# AT32F413 register map
Vendor: Keil; Series: AT32F413; File version: 1.0
CPU: CM4 r0p1, little endian, no MPU, FPU, 4 interrupt priority bits
Registers are 32-bit, read-write, reset 0x0 unless marked. A register's access mark holds for its fields unless they carry their own. Offsets are from the block's base; [hi:lo] are bit positions; {n}, {i} and the like mark numbered series; 'fields as' and 'values as' point back to an identical list.

## EXINT
Base 0x40010400
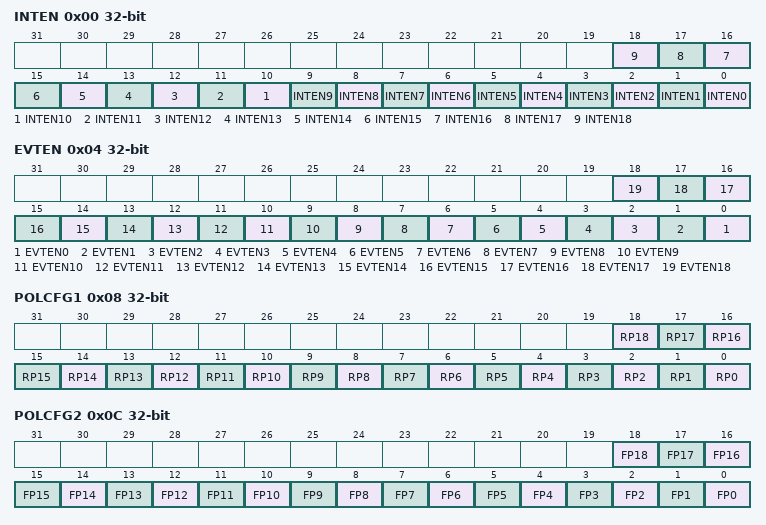
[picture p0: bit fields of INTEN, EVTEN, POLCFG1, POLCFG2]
0x00 INTEN — Interrupt enable register
  [n] INTEN{n} (n=0..18) — Interrupt enable or disable on line {n}
    on read: 0=Disabled (Interrupt request is disabled); 1=Enabled (Interrupt request is enabled) | on write: 0=Disable (Interrupt request disable); 1=Enable (Interrupt request enable)
0x04 EVTEN — Event enable register
  [n] EVTEN{n} (n=0..18) — Event enable or disable on line {n}
    on read: 0=Disabled (Event request is disabled); 1=Enabled (Event request is enabled) | on write: 0=Disable (Event request disable); 1=Enable (Event request enable)
0x08 POLCFG1 — Rising polarity configuration register
  [n] RP{n} (n=0..18) — Rising polarity configuration bit on line {n}
    on read: 0=Disabled (Rising trigger is disabled); 1=Enabled (Rising trigger is enabled) | on write: 0=Disable (Rising trigger disable); 1=Enable (Rising trigger enable)
0x0C POLCFG2 — Falling polarity configuration register
  [n] FP{n} (n=0..18) — Falling polarity configuration bit on line {n}
    on read: 0=Disabled (Falling polarity is disabled); 1=Enabled (Falling polarity is enabled) | on write: 0=Disable (Falling polarity disable); 1=Enable (Falling polarity enable)
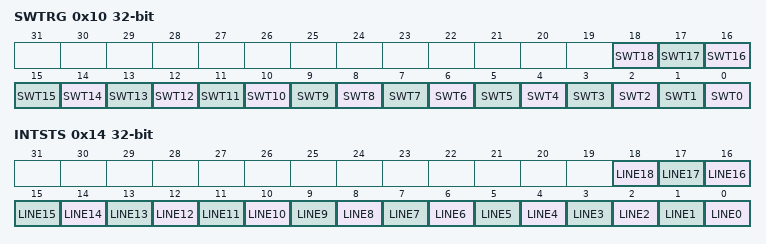
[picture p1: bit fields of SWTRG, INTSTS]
0x10 SWTRG — Software triggle register
  [n] SWT{n} (n=0..18) write-1-sets — Software trigger on line {n}
    on read: 0=NoTrigger (Default value); 1=Triggered (Software trigger generated) | on write: 1=Trigger (Generate trigger)
0x14 INTSTS — Interrupt status register
  [n] LINE{n} (n=0..18) write-1-clears — Line {n} status bit
    on read: 0=No interrupt occurred; 1=Interrupt occurred | on write: 1=Clear status flag

## RTC — Real time clock
Base 0x40002800
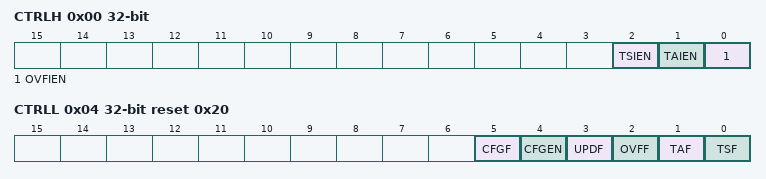
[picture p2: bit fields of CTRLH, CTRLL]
0x00 CTRLH — RTC Control Register High
  [2] TSIEN — Time second interrupt enable
  [1] TAIEN — Time alarm interrupt enable
  [0] OVFIEN — Overflow interrupt enable
0x04 CTRLL reset 0x20 — RTC Control Register Low
  [5] CFGF ro — RTC configuration finish
  [4] CFGEN — RTC configuration enable
  [3] UPDF — RTC update finish
  [2] OVFF — Overflow Flag
  [1] TAF — Time alarm flag
  [0] TSF — Time second flag
0x08 DIVH wo — RTC Divider Register High
  [3:0] DIV — RTC divider high
0x0C DIVL wo reset 0x8000 — RTC Divider Register Low
  [15:0] DIV — RTC divider low
0x10 DIVCNTH — RTC Divider Register High
  [3:0] DIVCNT — RTC divider register high
0x14 DIVCNTL reset 0x8000 — RTC Divider Register Low
  [15:0] DIVCNT — RTC divider register low
0x18 CNTH — RTC Counter Register High
  [15:0] CNT — RTC counter register high
0x1C CNTL — RTC Counter Register Low
  [15:0] CNT — RTC counter register low
0x20 TAH wo reset 0xFFFF — RTC Alarm Register High
  [15:0] TA — Time alarm register high
0x24 TAL wo reset 0xFFFF — Time alarm register low
  [15:0] TA — RTC alarm register low

## BPR — Battery powered register
Base 0x40006C04
0x00 DT{i} (i=1..10; step 0x4) — Battery powered domain data register {i}
  [15:0] DT — BPR data
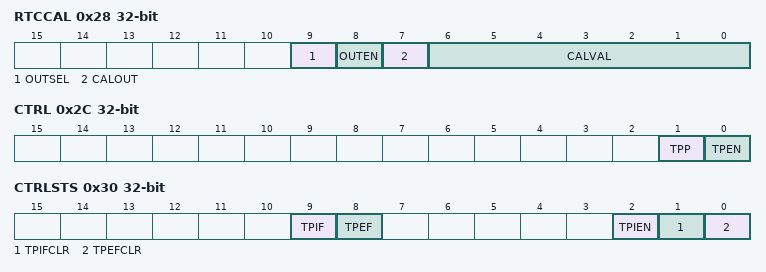
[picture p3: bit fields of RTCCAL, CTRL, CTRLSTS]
0x28 RTCCAL — RTC clock calibration register (BPR_RTCCAL)
  [9] OUTSEL write-1-sets — Output selection
    on read: 0=RTC (RTC alarm event output); 1=Second event output | on write: 1=Second event output
  [8] OUTEN write-1-sets — Output enable
    on read: 0=Disabled (Output is disabled); 1=Enabled (Output is enabled) | on write: 1=Enable (Output enable)
  [7] CALOUT write-1-sets — Calibration Clock Output
    on read: 0=NoOutput (No effect); 1=Output the RTC clock with a frequency divided by 64 on the TAMPER pin | on write: 1=Output the RTC clock with a frequency divided by 64 on the TAMPER pin
  [6:0] CALVAL — Calibration value
0x2C CTRL — BPR control register (BPR_CTRL)
  [1] TPP — TAMPER pin polarity
    0=High (Active high); 1=Low (Active low)
  [0] TPEN — Tamper pin enable
    on read: 0=Disabled (TAMPER pin is disabled); 1=Enabled (TAMPER pin is enabled) | on write: 0=Disable (TAMPER pin disable); 1=Enable (TAMPER pin enable)
0x30 CTRLSTS — BPR control/status register (BPR_CTRLSTS)
  [9] TPIF — Tamper interrupt flag
    on read: 0=NoEvent (No tamper event); 1=Event (A tamper event is detected)
  [8] TPEF — Tamper event flag
    values as TPIF
  [2] TPIEN — Tamper pin interrupt enable
    on read: 0=Disabled (Tamper pin interrupt is disabled); 1=Enabled (Tamper pin interrupt is enabled) | on write: 0=Disable (Tamper pin interrupt disable); 1=Enable (Tamper pin interrupt enable)
  [1] TPIFCLR wo write-1-clears — Tamper interrupt flag clear
    1=Clear (Tamper interrupt flag clear)
  [0] TPEFCLR wo write-1-clears — Tamper event flag clear
    1=Clear the tamper event flag
{0x10+4i} DT{i} (i=11..42) — Battery powered domain data register {i}
  [15:0] DT — BPR data
